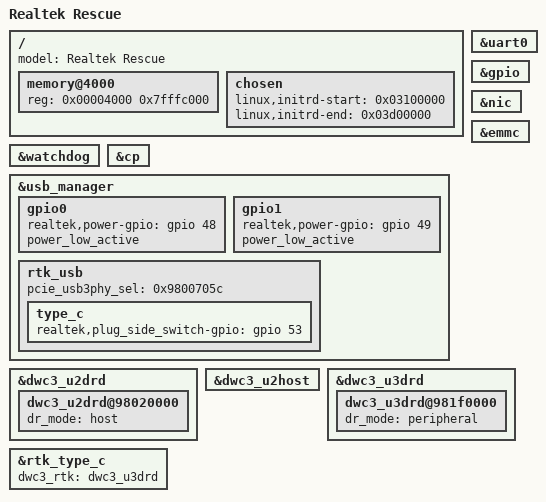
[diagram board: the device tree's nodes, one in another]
// SPDX-License-Identifier: (GPL-2.0-or-later OR BSD-2-Clause)
/*
 * Copyright (c) 2019-2020 Realtek Semiconductor Corp.
 */

/dts-v1/;

#include "rtd13xx.dtsi"

/ {
	model = "Realtek Rescue";

	memory@4000 {
		device_type = "memory";
		reg = <0x00004000 0x7fffc000>; /* boot ROM to 1 GiB or 2 GiB */
	};

	chosen {
		linux,initrd-start = <0x03100000>;
		linux,initrd-end = <0x03d00000>;
	};
};

/* debug console (J1) */
&uart0 {
	status = "okay";
};

&gpio {
	status = "okay";
};

&watchdog {
	status = "okay";
};

&nic {
	status = "okay";
};

&emmc {
	status = "okay";
};

&cp {
	status = "okay";
};

&usb_manager {
	status = "okay";

	gpio0 {
		realtek,power-gpio = <&gpio 48 GPIO_ACTIVE_HIGH>;
		power_low_active;
	};

	gpio1 {
		realtek,power-gpio = <&gpio 49 GPIO_ACTIVE_HIGH>;
		power_low_active;
	};

	rtk_usb {
		pcie_usb3phy_sel = <0x9800705c>; /* Only for RTD1319 */
			type_c {
			/* For 1319, u3drd */
			realtek,plug_side_switch-gpio = <&gpio 53 GPIO_ACTIVE_HIGH>;
		};

	};
};

&dwc3_u2drd {
	status = "okay";

	dwc3_u2drd@98020000 {
		dr_mode = "host"; /*host, peripheral*/
		status = "okay";
	};
};

&dwc3_u2host {
	status = "okay";
};

&dwc3_u3drd {
	status = "okay";

	dwc3_u3drd@981f0000 {
		dr_mode = "peripheral"; /*host, peripheral*/
		status = "okay";
	};
};

&rtk_type_c {
	status = "okay";

	dwc3_rtk = <&dwc3_u3drd>;
};
